AUTOSAR XML (schema 4-2-2)
package /MY_DATA_TYPES
  base type DATA_uint8: category=FIXED_LENGTH, base-type-size=8, base-type-encoding=NONE, mem-alignment=1, native-declaration=unigned char
  impl type myuint8: category=VALUE, base-type=DATA_uint8, range phys 0..255, raw 0..255
package /INTERFACES
  sender receiver interface SRI_DOOR_STATE
    data DOOR_STATE: type=myuint8
  client server interface CSI_DOOR_SENSOR
    operation DOOR_SENSOR
      arg LED_STATE: type=myuint8, direction=IN
    error E_OK: error-code=0
    error E_NOT_OK: error-code=1
package /DOOR_INDICATOR_SWCOMPONENTS
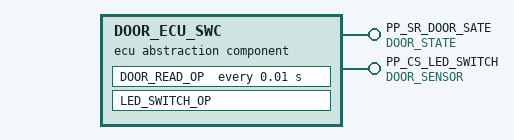
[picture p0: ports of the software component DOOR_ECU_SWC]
  ecu abstraction sw component type DOOR_ECU_SWC
    provide port PP_SR_DOOR_SATE: provided-interface=DOOR_STATE
    provide port PP_CS_LED_SWITCH: provided-interface=DOOR_SENSOR
    behavior ECU_SWC_RUNNABLES
      timing event TE_10ms: start-on-event=DOOR_READ_OP, period=0.01
      operation invoked event OIV_LED_SWITCH: start-on-event=LED_SWITCH_OP, operation=PP_CS_LED_SWITCH.LED_STATE
      runnable DOOR_READ_OP: symbol=DOOR_READ_OP_RUNNABLE
        data-write-access:
          access SENSOR_VAL: accessed-variable=PP_SR_DOOR_SATE.DOOR_STATE
      runnable LED_SWITCH_OP: symbol=LED_SWITCH_OP_RUNNABLE
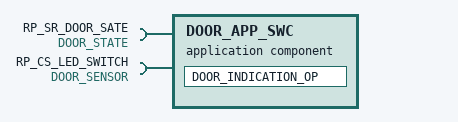
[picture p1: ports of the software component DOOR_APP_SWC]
  application sw component type DOOR_APP_SWC
    require port RP_SR_DOOR_SATE: required-interface=DOOR_STATE
    require port RP_CS_LED_SWITCH: required-interface=DOOR_SENSOR
    behavior APP_SWC_RUNNABLES
      timing event TE_12ms: start-on-event=DOOR_STATE
      runnable DOOR_INDICATION_OP
        data-read-access:
          access DOOR_STATE: accessed-variable=RP_SR_DOOR_SATE.DOOR_STATE
        sync call SERVER_CALL: operation=RP_SR_DOOR_SATE.DOOR_SENSOR
package /COMPOSITIONS
  composition sw component type TOP_LEVEL_COMPOSITION
    component ECU_SWC_PROTO: type=DOOR_ECU_SWC
    component APP_SWC_PROTO: type=DOOR_APP_SWC
    connect ECU_SWC_PROTO.PP_SR_DOOR_SATE -> APP_SWC_PROTO.RP_SR_DOOR_SATE
    connect ECU_SWC_PROTO.PP_CS_LED_SWITCH -> APP_SWC_PROTO.RP_CS_LED_SWITCH
